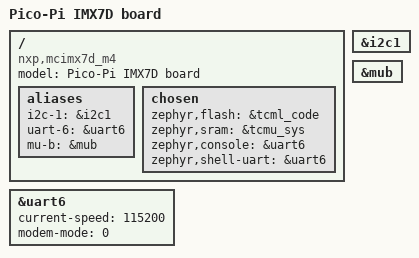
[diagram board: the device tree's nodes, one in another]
/*
 * Copyright (c) 2019, Joris Offouga
 *
 * SPDX-License-Identifier: Apache-2.0
 */

/dts-v1/;

#include <nxp/nxp_imx7d_m4.dtsi>

/ {
	model = "Pico-Pi IMX7D board";
	compatible = "nxp,mcimx7d_m4";

	aliases {
		i2c-1  = &i2c1;
		uart-6 = &uart6;
		mu-b = &mub;
	};

	chosen {
		zephyr,flash = &tcml_code;
		zephyr,sram = &tcmu_sys;
		zephyr,console = &uart6;
		zephyr,shell-uart = &uart6;
	};
};

&i2c1 {
	status = "okay";
};

&uart6 {
	status = "okay";
	current-speed = <115200>;
	modem-mode = <0>;
};

&mub {
	status = "okay";
};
